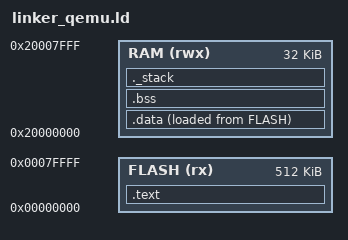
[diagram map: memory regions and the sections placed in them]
ENTRY(Reset_Handler)

MEMORY
{
  FLASH (rx)  : ORIGIN = 0x00000000, LENGTH = 512K
  RAM   (rwx) : ORIGIN = 0x20000000, LENGTH = 32K
}

SECTIONS
{
  .text :
  {
    KEEP(*(.isr_vector))
    *(.text*)
    *(.rodata*)
    *(.glue_7)
    *(.glue_7t)
    *(.ARM.exidx*)     /* ⭐ 關鍵：把 .ARM.exidx 加入 .text 區段 */
    . = ALIGN(4);
    _etext = .;
  } > FLASH

  .data : {
    _sdata = .;
    *(.data)
    . = ALIGN(4);
    _edata = .;
  } > RAM AT > FLASH

  .bss :
  {
    _sbss = .;
    *(.bss*)
    *(COMMON)
    . = ALIGN(4);
    _ebss = .;
  } > RAM

  ._stack :
  {
    . = ALIGN(8);
    _stack_top = .;
  } > RAM
}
